# LPC8N04 register map
Vendor: nxp.com; File version: 1.0
CPU: CM0PLUS r0p0, little endian, no MPU, no FPU, VTOR, 2 interrupt priority bits
Registers are 32-bit, read-write, reset 0x0 unless marked. A register's access mark holds for its fields unless they carry their own. Offsets are from the block's base; [hi:lo] are bit positions; {n}, {i} and the like mark numbered series; 'fields as' and 'values as' point back to an identical list.

## RTC — Real time clock timer
Base 0x40054000
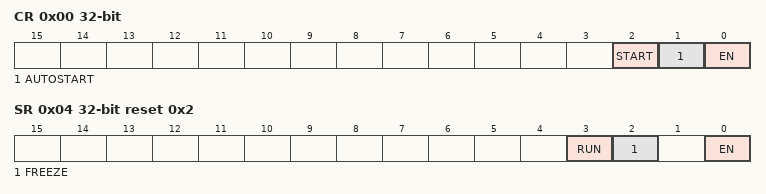
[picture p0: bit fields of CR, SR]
0x00 CR — RTC control register
  [2] START — Writing a 1 starts the countdown from the value stored in RTCSLEEPT until 0 is reached. Write 0 to clear. This bit is also cleared when the interrupt is asserted or a new value is written into the RTCSLEEPT register.
  [1] AUTOSTART — (1) Automatic timer start when value is written to RTCSLEEPT register, (0) manual start
  [0] EN — (1) Enable the RTC On/Off Timer, (0) disable
0x04 SR reset 0x2 — RTC status register
  [3] RUN ro — RTC timer is running
  [2] FREEZE ro — Asserted in the neighbourhood of edges on the internal tick clock. Values written to the RTCSLEEPT register during FREEZE=1 are delayed until after this conditions clears.
  [0] EN ro — RTC on/off timer enabled (1) or disabled (0)
0x08 CAL reset 0x8000 — RTC calibration value
  [15:0] CALIB — This value indicates the number of TFRO clock pulses in one tick.
0x0C SLEEPT — RTC Sleep time
  [23:0] SLEEPTIME — This value indicates the time to sleep in ticks.
0x10 VAL — Current RTC counter value
  [23:0] TIMEREMAIN ro — Current value (remaining time) of the countdown timer
0x14 IMIS — Interrupt mask register
  [0] IE — Software should set this bit to enable interrupt when the countdown is finished.
0x18 RIS — Raw Interrupt status register
  [0] RIS ro — This bit is 1 when the countdown has finished
0x1C MIS — Masked interrupt status register
  [0] MIS ro — This bit is 1 when the RTC countdown has finished and this interrupt is enabled.
0x20 ICR wo — Interrupt clear register
  [0] IC — Writing a 1 clears the countdown done interrupt
0x24 ACCSTAT — Access status register
  [0] READY ro — (0) RTC access not possible, (1) RTC access possible
0x30 TIME — RTC Time register
  [31:0] TIME — Current timer value

## RFIDNFC — RFID and NFC
Base 0x40058000
0x00 CFG — RFID/NFC configuration register
  [0] BYPASS — when set, the shared memory interface and registers are deactivated, and the external reader gets full access to the RFID/NFC EEPROM.
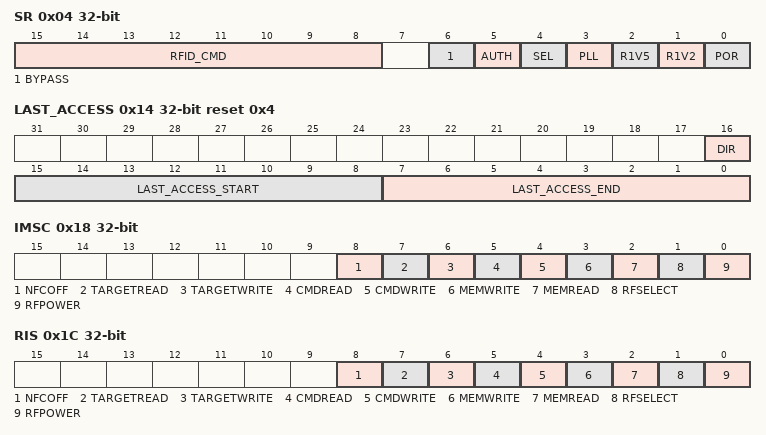
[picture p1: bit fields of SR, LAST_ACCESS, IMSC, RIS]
0x04 SR — RFID/NFC status register
  [15:8] RFID_CMD ro — Last RFID command received
    0=REQA; 1=WUPA; 2=ANTICOLLISION; 3=SELECT; 4=HLTA; 5=READ; 6=COMP_WRITE; 7=WRITE; 8=INCR_CNT; 9=READ_CNT; 10=PWD_AUTH; 11=GET_VERSION; 12=FAST_READ; 13=READ_SIG; 15=CHECK_TEARING_EVENT
  [6] BYPASS ro — RFID interface in Bypass mode
  [5] AUTH ro — RFID password for access authenticated
  [4] SEL ro — RFID selected
  [3] PLL ro — RFID PLL locked
  [2] R1V5 ro — Rectifier less than 1.5 V output warning
  [1] R1V2 ro — Rectifier less than 1.2 V output warning
  [0] POR ro — Power-on detected in the RFID analog core
0x08 CMDIN ro — RFID/NFC incoming command
  [31:0] CMDIN — Incoming command
0x0C CMDOUT — RFID/NFC outgoing command
  [31:0] CMDOUT — Outgoing data
0x10 TARGET reset 0x4 — RFID/NFC target page address register
  [7:0] PAGE — target (RF) page address
0x14 LAST_ACCESS reset 0x4 — raw Interrupt status register
  [16] DIR ro — direction of last accessed page (0) READ, (1) WRITE
  [15:8] LAST_ACCESS_START ro — last accessed (RF) page address (start of range)
  [7:0] LAST_ACCESS_END ro — last accessed (RF) page address (end of range)
0x18 IMSC — Interrupt mask register
  [8] NFCOFF — set to enable interrupt when external reader powers down RFID/NFC front-end
  [7] TARGETREAD — set to enable interrupt when reader reads from address specified in the TARGET register
  [6] TARGETWRITE — set to enable interrupt when reader writes to address specified in the TARGET register
  [5] CMDREAD — set to enable interrupt when reader reads the CMDOUT register
  [4] CMDWRITE — set to enable interrupt when reader writers to CMDIN register
  [3] MEMWRITE — set to enable interrupt when reader writes to shared memory (SHARED_MEM)
  [2] MEMREAD — set to enable interrupt when reader reads from shared memory (SHARED_MEM)
  [1] RFSELECT — set to enable interrupt when reader selects tag
  [0] RFPOWER — set to enable interrupt when RFID power is detected
0x1C RIS — Raw Interrupt status register
  [8] NFCOFF ro — set to enable interrupt when external reader powers down RFID/NFC front-end
  [7] TARGETREAD ro — set to enable interrupt when reader reads from address specified in the TARGET register
  [6] TARGETWRITE ro — set to enable interrupt when reader writes to address specified in the TARGET register
  [5] CMDREAD ro — set to enable interrupt when reader reads the CMDOUT register
  [4] CMDWRITE ro — set to enable interrupt when reader writers to CMDIN register
  [3] MEMWRITE ro — set to enable interrupt when reader writes to shared memory (SHARED_MEM)
  [2] MEMREAD ro — set to enable interrupt when reader reads from shared memory (SHARED_MEM)
  [1] RFSELECT ro — set to enable interrupt when reader selects tag
  [0] RFPOWER ro — set to enable interrupt when RFID power is detected
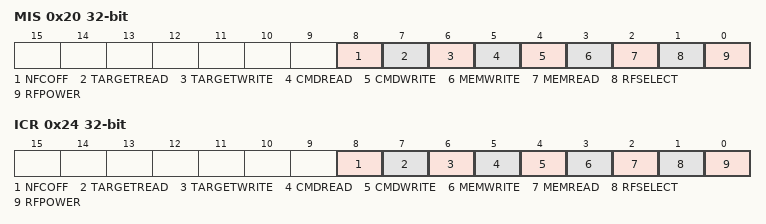
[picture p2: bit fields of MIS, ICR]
0x20 MIS — Masked interrupt status register
  fields as RIS
0x24 ICR wo — Interrupt clear register
  fields as IMSC
{0x100+4i} SHARED_MEM[{i}] (i=0..127) reset not defined — POR captured value of port n
  [31:0] SHAREDMEM — buffer memory space

## Notices in the file
The Clear BSD License
Copyright 2016-2018 NXP
All rights reserved.
Redistribution and use in source and binary forms, with or without
modification, are permitted (subject to the limitations in the
disclaimer below) provided that the following conditions are met:
Redistributions of source code must retain the above copyright
notice, this list of conditions and the following disclaimer.
Redistributions in binary form must reproduce the above copyright
notice, this list of conditions and the following disclaimer in the
documentation and/or other materials provided with the distribution.
Neither the name of the copyright holder nor the names of its
contributors may be used to endorse or promote products derived from
this software without specific prior written permission.
NO EXPRESS OR IMPLIED LICENSES TO ANY PARTY'S PATENT RIGHTS ARE
GRANTED BY THIS LICENSE. THIS SOFTWARE IS PROVIDED BY THE COPYRIGHT
HOLDERS AND CONTRIBUTORS "AS IS" AND ANY EXPRESS OR IMPLIED
WARRANTIES, INCLUDING, BUT NOT LIMITED TO, THE IMPLIED WARRANTIES OF
MERCHANTABILITY AND FITNESS FOR A PARTICULAR PURPOSE ARE
DISCLAIMED. IN NO EVENT SHALL THE COPYRIGHT HOLDER OR CONTRIBUTORS BE
LIABLE FOR ANY DIRECT, INDIRECT, INCIDENTAL, SPECIAL, EXEMPLARY, OR
CONSEQUENTIAL DAMAGES (INCLUDING, BUT NOT LIMITED TO, PROCUREMENT OF
SUBSTITUTE GOODS OR SERVICES; LOSS OF USE, DATA, OR PROFITS; OR
BUSINESS INTERRUPTION) HOWEVER CAUSED AND ON ANY THEORY OF LIABILITY,
WHETHER IN CONTRACT, STRICT LIABILITY, OR TORT (INCLUDING NEGLIGENCE
OR OTHERWISE) ARISING IN ANY WAY OUT OF THE USE OF THIS SOFTWARE, EVEN
IF ADVISED OF THE POSSIBILITY OF SUCH DAMAGE.
